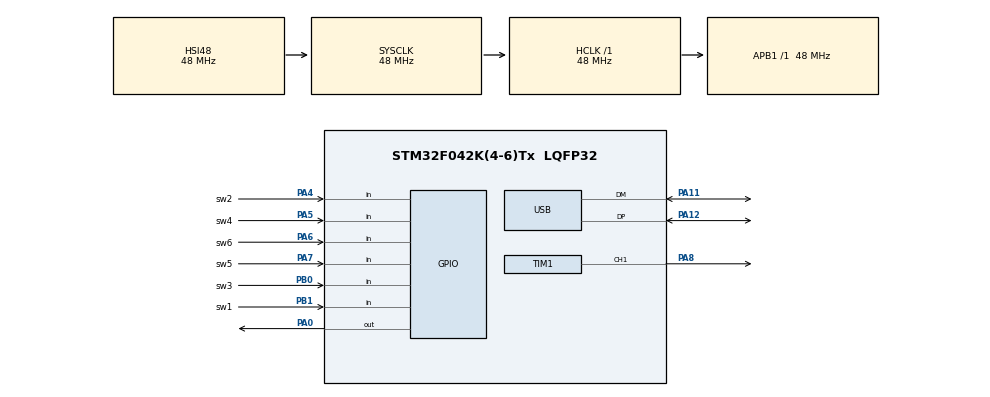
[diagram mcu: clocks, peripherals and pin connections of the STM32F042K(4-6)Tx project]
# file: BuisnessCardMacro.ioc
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Mcu.Family=STM32F0
Mcu.Name=STM32F042K(4-6)Tx
Mcu.Package=LQFP32
NVIC.USB_IRQn=true\:0\:0\:false\:false\:true\:false\:true
PA0.Signal=GPIO_Output
PA11.Mode=Device
PA11.Signal=USB_DM
PA12.Mode=Device
PA12.Signal=USB_DP
PA13.Mode=Serial_Wire
PA13.Signal=SYS_SWDIO
PA14.Mode=Serial_Wire
PA14.Signal=SYS_SWCLK
PA4.GPIO_Label=sw2
PA4.Signal=GPIO_Input
PA5.GPIO_Label=sw4
PA5.Signal=GPIO_Input
PA6.GPIO_Label=sw6
PA6.Signal=GPIO_Input
PA7.GPIO_Label=sw5
PA7.Signal=GPIO_Input
PA8.Signal=S_TIM1_CH1
PB0.GPIO_Label=sw3
PB0.Signal=GPIO_Input
PB1.GPIO_Label=sw1
PB1.Signal=GPIO_Input
ProjectManager.HeapSize=0x200
ProjectManager.StackSize=0x400
ProjectManager.TargetToolchain=Makefile
RCC.AHBFreq_Value=48000000
RCC.APB1Freq_Value=48000000
RCC.APB1TimFreq_Value=48000000
RCC.HCLKFreq_Value=48000000
RCC.SYSCLKFreq_VALUE=48000000
RCC.SYSCLKSource=RCC_SYSCLKSOURCE_HSI48
SH.S_TIM1_CH1.0=TIM1_CH1,PWM Generation1 CH1
TIM1.Channel-PWM\ Generation1\ CH1=TIM_CHANNEL_1
USB_DEVICE.CLASS_NAME_FS=HID
USB_DEVICE.VirtualMode=Hid
USB_DEVICE.VirtualModeFS=Hid_FS
VP_USB_DEVICE_VS_USB_DEVICE_HID_FS.Mode=HID_FS
board=custom

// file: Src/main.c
/* USER CODE BEGIN Header */
/**
  ******************************************************************************
  * @file           : main.c
  * @brief          : Main program body
  ******************************************************************************
  * @attention
  *
  * <h2><center>&copy; Copyright (c) 2021 STMicroelectronics.
  * All rights reserved.</center></h2>
  *
  * This software component is licensed by ST under Ultimate Liberty license
  * SLA0044, the "License"; You may not use this file except in compliance with
  * the License. You may obtain a copy of the License at:
  *                             www.st.com/SLA0044
  *
  ******************************************************************************
  */
/* USER CODE END Header */
#include "main.h"
#include "tim.h"
#include "usb_device.h"
#include "gpio.h"

void SystemClock_Config(void);

int main(void)
{

  /* MCU Configuration--------------------------------------------------------*/

  /* Reset of all peripherals, Initializes the Flash interface and the Systick. */
  HAL_Init();

  /* Configure the system clock */
  SystemClock_Config();

  /* Initialize all configured peripherals */
  MX_GPIO_Init();
  MX_TIM1_Init();
  //MX_USB_DEVICE_Init();

  /* Infinite loop */
  /* USER CODE BEGIN WHILE */
  while (1)
  {
    if(HAL_GPIO_ReadPin(sw1_GPIO_Port, sw1_Pin) == GPIO_PIN_RESET)
    {

    }
    /* USER CODE END WHILE */

  }
}

void SystemClock_Config(void)
{
  RCC_OscInitTypeDef RCC_OscInitStruct = {0};
  RCC_ClkInitTypeDef RCC_ClkInitStruct = {0};
  RCC_PeriphCLKInitTypeDef PeriphClkInit = {0};

  /** Initializes the RCC Oscillators according to the specified parameters
  * in the RCC_OscInitTypeDef structure.
  */
  RCC_OscInitStruct.OscillatorType = RCC_OSCILLATORTYPE_HSI48;
  RCC_OscInitStruct.HSI48State = RCC_HSI48_ON;
  RCC_OscInitStruct.PLL.PLLState = RCC_PLL_NONE;
  if (HAL_RCC_OscConfig(&RCC_OscInitStruct) != HAL_OK)
  {
    Error_Handler();
  }
  /** Initializes the CPU, AHB and APB buses clocks
  */
  RCC_ClkInitStruct.ClockType = RCC_CLOCKTYPE_HCLK|RCC_CLOCKTYPE_SYSCLK
                              |RCC_CLOCKTYPE_PCLK1;
  RCC_ClkInitStruct.SYSCLKSource = RCC_SYSCLKSOURCE_HSI48;
  RCC_ClkInitStruct.AHBCLKDivider = RCC_SYSCLK_DIV1;
  RCC_ClkInitStruct.APB1CLKDivider = RCC_HCLK_DIV1;

  if (HAL_RCC_ClockConfig(&RCC_ClkInitStruct, FLASH_LATENCY_1) != HAL_OK)
  {
    Error_Handler();
  }
  PeriphClkInit.PeriphClockSelection = RCC_PERIPHCLK_USB;
  PeriphClkInit.UsbClockSelection = RCC_USBCLKSOURCE_HSI48;

  if (HAL_RCCEx_PeriphCLKConfig(&PeriphClkInit) != HAL_OK)
  {
    Error_Handler();
  }
}

void Error_Handler(void)
{
  __disable_irq();
  while (1)
  {
  }
}

/************************ (C) COPYRIGHT STMicroelectronics *****END OF FILE****/
